AUTOSAR XML (schema 4-2-2)
package /Components
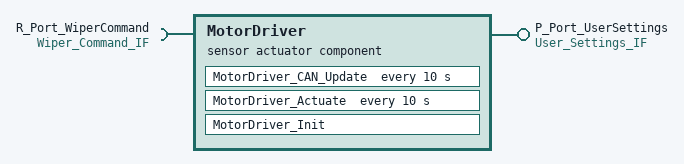
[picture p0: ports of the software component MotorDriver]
  sensor actuator sw component type MotorDriver
    provide port P_Port_UserSettings: provided-interface=User_Settings_IF
    require port R_Port_WiperCommand: required-interface=Wiper_Command_IF
    behavior MotorDriver_InternalBehavior
      init event MotorDriver_InitEvent: start-on-event=MotorDriver_Init
      timing event MotorDriver_CAN_UpdateEvent: start-on-event=MotorDriver_CAN_Update, period=10
      timing event MotorDriver_ActuateEvent: start-on-event=MotorDriver_Actuate, period=10
      runnable MotorDriver_Init
        data-send-points:
          access VA_WiperMode_Init: accessed-variable=P_Port_UserSettings.wiper_mode_auto
          access VA_FrontManual_Init: accessed-variable=P_Port_UserSettings.front_manual_speed
          access VA_RearManual_Init: accessed-variable=P_Port_UserSettings.rear_manual_speed
      runnable MotorDriver_CAN_Update: minimum-start-interval=10
        data-send-points:
          access VA_WiperMode_CAN: accessed-variable=P_Port_UserSettings.wiper_mode_auto
          access VA_FrontManual_CAN: accessed-variable=P_Port_UserSettings.front_manual_speed
          access VA_RearManual_CAN: accessed-variable=P_Port_UserSettings.rear_manual_speed
      runnable MotorDriver_Actuate: minimum-start-interval=10
        data-receive-point-by-arguments:
          access VA_FrontCmd_Read: accessed-variable=R_Port_WiperCommand.front_wiper_cmd
          access VA_RearCmd_Read: accessed-variable=R_Port_WiperCommand.rear_wiper_cmd
